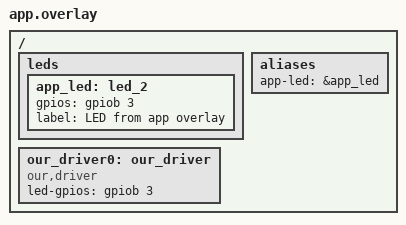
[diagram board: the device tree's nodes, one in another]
/ { 
    leds {
        app_led: led_2 { 
            gpios = <&gpiob 3 GPIO_ACTIVE_HIGH>;
            label = "LED from app overlay";
        };
    };

    aliases {
		app-led = &app_led;
	};

    our_driver0: our_driver {
        compatible = "our,driver";
        status = "okay";
        led-gpios = <&gpiob 3 GPIO_ACTIVE_HIGH>;
    };
};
